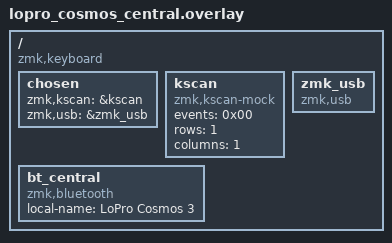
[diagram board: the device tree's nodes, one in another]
 / {

    compatible = "zmk,keyboard";

    chosen {

        zmk,kscan = &kscan;
        zmk,usb = &zmk_usb;      /* <--- tie the USB node explicitly */

    };


    kscan: kscan {

        compatible = "zmk,kscan-mock";
        events = <0x00>;         /* required placeholder */
        rows = <1>;
        columns = <1>;

    };


    zmk_usb: zmk_usb {

        compatible = "zmk,usb";
        status = "okay";

    };


    bt_central: bt_central {

        compatible = "zmk,bluetooth";
        local-name = "LoPro Cosmos 3";

    };

}; 









